VERSION ""

NS_ :

BS_:

BU_: Hyperdrive Host

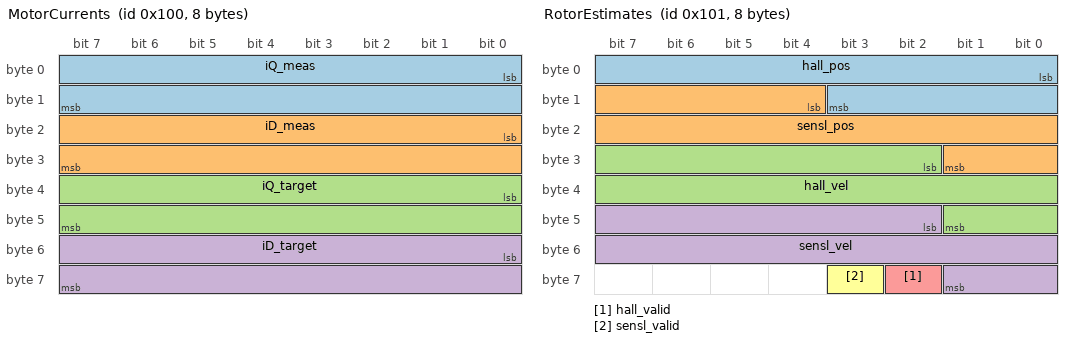
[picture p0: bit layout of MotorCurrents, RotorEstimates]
BO_ 256 MotorCurrents: 8 Hyperdrive
 SG_ iQ_meas : 0|16@1- (0.001,0) [-32.768|32.767] "A" Host
 SG_ iD_meas : 16|16@1- (0.001,0) [-32.768|32.767] "A" Host
 SG_ iQ_target : 32|16@1- (0.001,0) [-32.768|32.767] "A" Host
 SG_ iD_target : 48|16@1- (0.001,0) [-32.768|32.767] "A" Host

BO_ 257 RotorEstimates: 8 Hyperdrive
 SG_ hall_pos : 0|12@1+ (0.0015339808,0) [0|6.2817] "rad" Host
 SG_ sensl_pos : 12|14@1+ (0.00038349519,0) [0|6.2829] "rad" Host
 SG_ hall_vel : 26|16@1- (0.25,0) [-8192|8191.75] "rad/s" Host
 SG_ sensl_vel : 42|16@1- (0.25,0) [-8192|8191.75] "rad/s" Host
 SG_ hall_valid : 58|1@1+ (1,0) [0|1] "" Host
 SG_ sensl_valid : 59|1@1+ (1,0) [0|1] "" Host

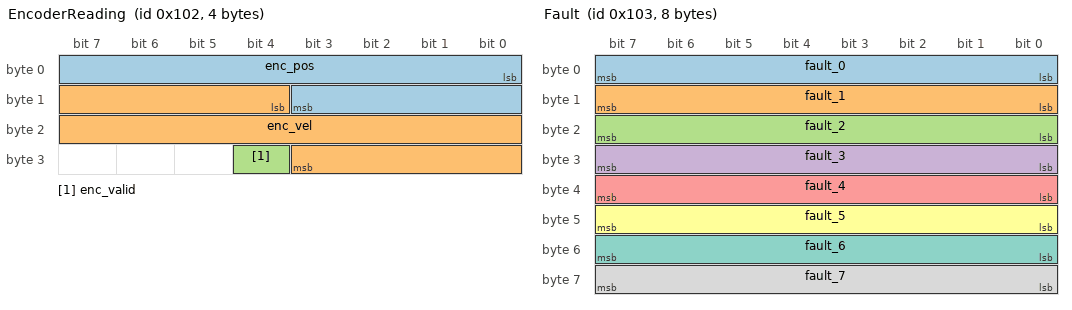
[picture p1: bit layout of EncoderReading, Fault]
BO_ 258 EncoderReading: 4 Hyperdrive
 SG_ enc_pos : 0|12@1+ (0.0015339808,0) [0|6.2817] "rad" Host
 SG_ enc_vel : 12|16@1- (0.25,0) [-8192|8191.75] "rad/s" Host
 SG_ enc_valid : 28|1@1+ (1,0) [0|1] "" Host

BO_ 259 Fault: 8 Hyperdrive
 SG_ fault_0 : 0|8@1+ (1,0) [0|255] "" Host
 SG_ fault_1 : 8|8@1+ (1,0) [0|255] "" Host
 SG_ fault_2 : 16|8@1+ (1,0) [0|255] "" Host
 SG_ fault_3 : 24|8@1+ (1,0) [0|255] "" Host
 SG_ fault_4 : 32|8@1+ (1,0) [0|255] "" Host
 SG_ fault_5 : 40|8@1+ (1,0) [0|255] "" Host
 SG_ fault_6 : 48|8@1+ (1,0) [0|255] "" Host
 SG_ fault_7 : 56|8@1+ (1,0) [0|255] "" Host

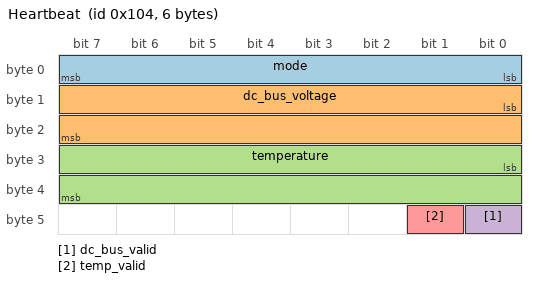
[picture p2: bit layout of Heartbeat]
BO_ 260 Heartbeat: 6 Hyperdrive
 SG_ mode : 0|8@1+ (1,0) [0|255] "" Host
 SG_ dc_bus_voltage : 8|16@1+ (0.01,0) [0|655.35] "V" Host
 SG_ temperature : 24|16@1- (0.1,0) [-3276.8|3276.7] "degC" Host
 SG_ dc_bus_valid : 40|1@1+ (1,0) [0|1] "" Host
 SG_ temp_valid : 41|1@1+ (1,0) [0|1] "" Host

BO_ 320 Setpoint: 4 Host
 SG_ target_torque : 0|16@1- (0.001,0) [-32.768|32.767] "Nm" Hyperdrive
 SG_ target_velocity : 16|16@1- (0.25,0) [-8192|8191.75] "rad/s" Hyperdrive

BO_ 321 ControlCommand: 1 Host
 SG_ command : 0|8@1+ (1,0) [0|255] "" Hyperdrive

BO_ 322 ConfigWrite: 5 Host
 SG_ param_id : 0|8@1+ (1,0) [0|255] "" Hyperdrive
 SG_ value_bits : 8|32@1+ (1,0) [0|4294967295] "" Hyperdrive

CM_ SG_ 260 mode "0=Idle 1=Calibration 2=TorqueControl 3=VelocityControl 4=Fault";

BA_DEF_ BO_  "GenMsgCycleTimeUs" INT 0 1000000;
BA_DEF_DEF_  "GenMsgCycleTimeUs" 0;
BA_ "GenMsgCycleTimeUs" BO_ 256 400;
BA_ "GenMsgCycleTimeUs" BO_ 257 1000;
BA_ "GenMsgCycleTimeUs" BO_ 258 1000;
BA_ "GenMsgCycleTimeUs" BO_ 259 100000;
BA_ "GenMsgCycleTimeUs" BO_ 260 100000;

VAL_ 321 command 0 "Idle" 1 "StartCalibration" 2 "TorqueControl" 3 "VelocityControl" 4 "ClearFault" ;
VAL_ 322 param_id 0 "current_limit" 1 "num_pole_pairs" 2 "calibration_voltage" 3 "calibration_current" 4 "calibration_omega" ;
